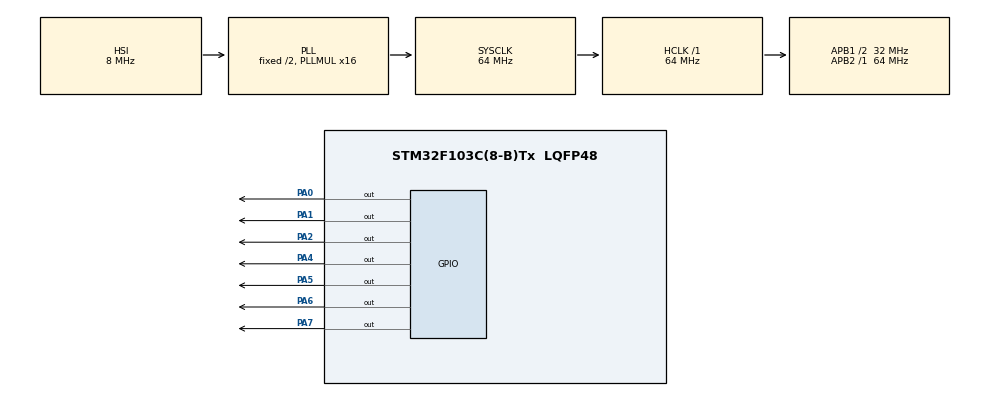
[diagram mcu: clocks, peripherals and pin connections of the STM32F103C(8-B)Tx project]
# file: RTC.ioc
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Mcu.Family=STM32F1
PC15-OSC32_OUT.Mode=LSE-External-Oscillator
VP_RTC_VS_RTC_Activate.Mode=RTC_Enabled
RCC.APB1CLKDivider=RCC_HCLK_DIV2
PC14-OSC32_IN.Signal=RCC_OSC32_IN
RCC.SYSCLKSource=RCC_SYSCLKSOURCE_PLLCLK
ProjectManager.StackSize=0x400
PA0-WKUP.Signal=GPIO_Output
PA13.Signal=SYS_JTMS-SWDIO
ProjectManager.TargetToolchain=MDK-ARM V5.27
RCC.HCLKFreq_Value=64000000
RCC.APB2TimFreq_Value=64000000
RTC.Format=RTC_FORMAT_BIN
RCC.USBFreq_Value=64000000
PC15-OSC32_OUT.Signal=RCC_OSC32_OUT
PA1.Signal=GPIO_Output
RCC.AHBFreq_Value=64000000
PA5.Signal=GPIO_Output
board=custom
RCC.RTCClockSelection=RCC_RTCCLKSOURCE_LSE
RCC.PLLMUL=RCC_PLL_MUL16
RCC.APB2Freq_Value=64000000
PC14-OSC32_IN.Mode=LSE-External-Oscillator
PA14.Mode=Serial_Wire
PA13.Mode=Serial_Wire
Mcu.Name=STM32F103C(8-B)Tx
PA2.Signal=GPIO_Output
PA4.Signal=GPIO_Output
RCC.SYSCLKFreq_VALUE=64000000
Mcu.Package=LQFP48
PA6.Signal=GPIO_Output
PA14.Signal=SYS_JTCK-SWCLK
ProjectManager.HeapSize=0x200
NVIC.PriorityGroup=NVIC_PRIORITYGROUP_4
RCC.APB1TimFreq_Value=64000000
RCC.APB1Freq_Value=32000000
RTC.OutPut=RTC_OUTPUTSOURCE_ALARM
PA7.Signal=GPIO_Output

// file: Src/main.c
/* USER CODE BEGIN Header */
/**
  ******************************************************************************
  * @file           : main.c
  * @brief          : Main program body
  ******************************************************************************
  * @attention
  *
  * <h2><center>&copy; Copyright (c) 2021 STMicroelectronics.
  * All rights reserved.</center></h2>
  *
  * This software component is licensed by ST under BSD 3-Clause license,
  * the "License"; You may not use this file except in compliance with the
  * License. You may obtain a copy of the License at:
  *                        opensource.org/licenses/BSD-3-Clause
  *
  ******************************************************************************
  */
/* USER CODE END Header */
#include "main.h"

/* USER CODE BEGIN Includes */
#include "stlcd.h"
#include "stdio.h"
/* USER CODE END Includes */

RTC_HandleTypeDef hrtc;

/* USER CODE BEGIN PV */
RTC_TimeTypeDef time;
RTC_DateTypeDef date;

char str[16];
/* USER CODE END PV */

void SystemClock_Config(void);
static void MX_GPIO_Init(void);
static void MX_RTC_Init(void);

int main(void)
{

  /* MCU Configuration--------------------------------------------------------*/

  /* Reset of all peripherals, Initializes the Flash interface and the Systick. */
  HAL_Init();

  /* Configure the system clock */
  SystemClock_Config();

  /* Initialize all configured peripherals */
  MX_GPIO_Init();
  MX_RTC_Init();
  /* USER CODE BEGIN 2 */
	lcd_init();
  /* USER CODE END 2 */

  /* Infinite loop */
  while (1)
  {

    /* USER CODE BEGIN 3 */
		HAL_RTC_GetTime(&hrtc, &time, RTC_FORMAT_BIN);
		HAL_RTC_GetDate(&hrtc, &date, RTC_FORMAT_BIN);

		sprintf(str, "%02d:%02d:%02d", time.Hours, time.Minutes, time.Seconds);
		lcd_gotoxy(4,0);
		lcd_puts(str);

  }
  /* USER CODE END 3 */
}

void SystemClock_Config(void)
{
  RCC_OscInitTypeDef RCC_OscInitStruct = {0};
  RCC_ClkInitTypeDef RCC_ClkInitStruct = {0};
  RCC_PeriphCLKInitTypeDef PeriphClkInit = {0};

  /** Initializes the RCC Oscillators according to the specified parameters
  * in the RCC_OscInitTypeDef structure.
  */
  RCC_OscInitStruct.OscillatorType = RCC_OSCILLATORTYPE_HSI|RCC_OSCILLATORTYPE_LSE;
  RCC_OscInitStruct.LSEState = RCC_LSE_ON;
  RCC_OscInitStruct.HSIState = RCC_HSI_ON;
  RCC_OscInitStruct.HSICalibrationValue = RCC_HSICALIBRATION_DEFAULT;
  RCC_OscInitStruct.PLL.PLLState = RCC_PLL_ON;
  RCC_OscInitStruct.PLL.PLLSource = RCC_PLLSOURCE_HSI_DIV2;
  RCC_OscInitStruct.PLL.PLLMUL = RCC_PLL_MUL16;
  if (HAL_RCC_OscConfig(&RCC_OscInitStruct) != HAL_OK)
  {
    Error_Handler();
  }
  /** Initializes the CPU, AHB and APB buses clocks
  */
  RCC_ClkInitStruct.ClockType = RCC_CLOCKTYPE_HCLK|RCC_CLOCKTYPE_SYSCLK
                              |RCC_CLOCKTYPE_PCLK1|RCC_CLOCKTYPE_PCLK2;
  RCC_ClkInitStruct.SYSCLKSource = RCC_SYSCLKSOURCE_PLLCLK;
  RCC_ClkInitStruct.AHBCLKDivider = RCC_SYSCLK_DIV1;
  RCC_ClkInitStruct.APB1CLKDivider = RCC_HCLK_DIV2;
  RCC_ClkInitStruct.APB2CLKDivider = RCC_HCLK_DIV1;

  if (HAL_RCC_ClockConfig(&RCC_ClkInitStruct, FLASH_LATENCY_2) != HAL_OK)
  {
    Error_Handler();
  }
  PeriphClkInit.PeriphClockSelection = RCC_PERIPHCLK_RTC;
  PeriphClkInit.RTCClockSelection = RCC_RTCCLKSOURCE_LSE;
  if (HAL_RCCEx_PeriphCLKConfig(&PeriphClkInit) != HAL_OK)
  {
    Error_Handler();
  }
}

static void MX_RTC_Init(void)
{

  /** Initialize RTC Only
  */
  hrtc.Instance = RTC;
  hrtc.Init.AsynchPrediv = RTC_AUTO_1_SECOND;
  hrtc.Init.OutPut = RTC_OUTPUTSOURCE_ALARM;
  if (HAL_RTC_Init(&hrtc) != HAL_OK)
  {
    Error_Handler();
  }

}

static void MX_GPIO_Init(void)
{
  GPIO_InitTypeDef GPIO_InitStruct = {0};

  /* GPIO Ports Clock Enable */
  __HAL_RCC_GPIOC_CLK_ENABLE();
  __HAL_RCC_GPIOA_CLK_ENABLE();

  /*Configure GPIO pin Output Level */
  HAL_GPIO_WritePin(GPIOA, GPIO_PIN_0|GPIO_PIN_1|GPIO_PIN_2|GPIO_PIN_4
                          |GPIO_PIN_5|GPIO_PIN_6|GPIO_PIN_7, GPIO_PIN_RESET);

  /*Configure GPIO pins : PA0 PA1 PA2 PA4
                           PA5 PA6 PA7 */
  GPIO_InitStruct.Pin = GPIO_PIN_0|GPIO_PIN_1|GPIO_PIN_2|GPIO_PIN_4
                          |GPIO_PIN_5|GPIO_PIN_6|GPIO_PIN_7;
  GPIO_InitStruct.Mode = GPIO_MODE_OUTPUT_PP;
  GPIO_InitStruct.Pull = GPIO_NOPULL;
  GPIO_InitStruct.Speed = GPIO_SPEED_FREQ_LOW;
  HAL_GPIO_Init(GPIOA, &GPIO_InitStruct);

}

void Error_Handler(void)
{
  __disable_irq();
  while (1)
  {
  }
}

/************************ (C) COPYRIGHT STMicroelectronics *****END OF FILE****/
